VERSION ""

NS_ :

BS_:

BU_: LeanSensor Logger

BO_ 3221225472 VECTOR__INDEPENDENT_SIG_MSG: 0 Vector__XXX
 SG_ lean_1_7 : 0|18@1+ (0.01,0) [0|1310.71] "m" Vector__XXX
 SG_ lean_3_7 : 0|18@1+ (0.01,0) [0|1310.71] "m" Vector__XXX
 SG_ lean_3_8 : 0|18@1+ (0.01,0) [0|1310.71] "m" Vector__XXX
 SG_ lean_4_1 : 0|18@1+ (0.01,0) [0|1310.71] "m" Vector__XXX
 SG_ lean_4_2 : 0|18@1+ (0.01,0) [0|1310.71] "m" Vector__XXX
 SG_ lean_4_3 : 0|18@1+ (0.01,0) [0|1310.71] "m" Vector__XXX
 SG_ lean_4_4 : 0|18@1+ (0.01,0) [0|1310.71] "m" Vector__XXX
 SG_ lean_4_5 : 0|18@1+ (0.01,0) [0|1310.71] "m" Vector__XXX
 SG_ lean_4_6 : 0|18@1+ (0.01,0) [0|1310.71] "m" Vector__XXX
 SG_ lean_4_7 : 0|18@1+ (0.01,0) [0|1310.71] "m" Vector__XXX
 SG_ lean_4_8 : 0|18@1+ (0.01,0) [0|1310.71] "m" Vector__XXX
 SG_ lean_5_1 : 0|18@1+ (0.01,0) [0|1310.71] "m" Vector__XXX
 SG_ lean_5_2 : 0|18@1+ (0.01,0) [0|1310.71] "m" Vector__XXX
 SG_ lean_5_3 : 0|18@1+ (0.01,0) [0|1310.71] "m" Vector__XXX
 SG_ lean_5_4 : 0|18@1+ (0.01,0) [0|1310.71] "m" Vector__XXX
 SG_ lean_5_5 : 0|18@1+ (0.01,0) [0|1310.71] "m" Vector__XXX
 SG_ lean_5_6 : 0|18@1+ (0.01,0) [0|1310.71] "m" Vector__XXX
 SG_ lean_5_7 : 0|18@1+ (0.01,0) [0|1310.71] "m" Vector__XXX
 SG_ lean_5_8 : 0|18@1+ (0.01,0) [0|1310.71] "m" Vector__XXX
 SG_ lean_6_1 : 0|18@1+ (0.01,0) [0|1310.71] "m" Vector__XXX
 SG_ lean_6_2 : 0|18@1+ (0.01,0) [0|1310.71] "m" Vector__XXX
 SG_ lean_6_3 : 0|18@1+ (0.01,0) [0|1310.71] "m" Vector__XXX
 SG_ lean_6_4 : 0|18@1+ (0.01,0) [0|1310.71] "m" Vector__XXX
 SG_ lean_6_5 : 0|18@1+ (0.01,0) [0|1310.71] "m" Vector__XXX
 SG_ lean_6_6 : 0|18@1+ (0.01,0) [0|1310.71] "m" Vector__XXX
 SG_ lean_6_7 : 0|18@1+ (0.01,0) [0|1310.71] "m" Vector__XXX
 SG_ lean_6_8 : 0|18@1+ (0.01,0) [0|1310.71] "m" Vector__XXX
 SG_ lean_7_1 : 0|18@1+ (0.01,0) [0|1310.71] "m" Vector__XXX
 SG_ lean_7_2 : 0|18@1+ (0.01,0) [0|1310.71] "m" Vector__XXX
 SG_ lean_7_3 : 0|18@1+ (0.01,0) [0|1310.71] "m" Vector__XXX
 SG_ lean_7_4 : 0|18@1+ (0.01,0) [0|1310.71] "m" Vector__XXX
 SG_ lean_7_5 : 0|18@1+ (0.01,0) [0|1310.71] "m" Vector__XXX
 SG_ lean_7_6 : 0|18@1+ (0.01,0) [0|1310.71] "m" Vector__XXX
 SG_ lean_7_7 : 0|18@1+ (0.01,0) [0|1310.71] "m" Vector__XXX
 SG_ lean_7_8 : 0|18@1+ (0.01,0) [0|1310.71] "m" Vector__XXX
 SG_ lean_8_1 : 0|18@1+ (0.01,0) [0|1310.71] "m" Vector__XXX
 SG_ lean_8_2 : 0|18@1+ (0.01,0) [0|1310.71] "m" Vector__XXX
 SG_ lean_8_3 : 0|18@1+ (0.01,0) [0|1310.71] "m" Vector__XXX
 SG_ lean_8_4 : 0|18@1+ (0.01,0) [0|1310.71] "m" Vector__XXX
 SG_ lean_8_5 : 0|18@1+ (0.01,0) [0|1310.71] "m" Vector__XXX
 SG_ lean_8_6 : 0|18@1+ (0.01,0) [0|1310.71] "m" Vector__XXX
 SG_ lean_8_7 : 0|18@1+ (0.01,0) [0|1310.71] "m" Vector__XXX
 SG_ lean_8_8 : 0|18@1+ (0.01,0) [0|1310.71] "m" Vector__XXX

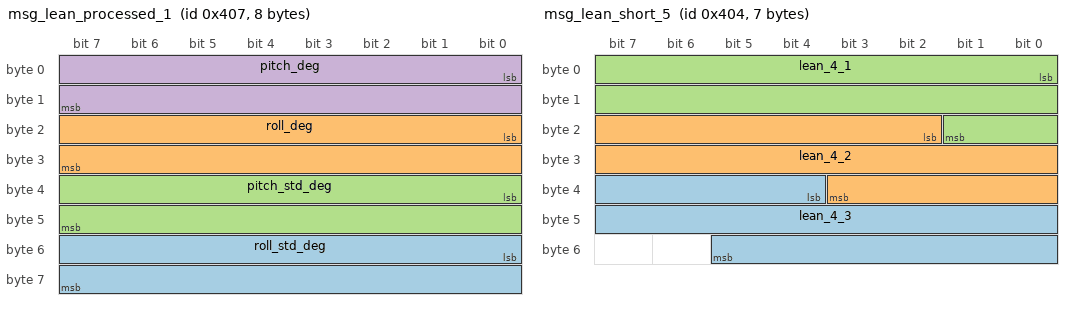
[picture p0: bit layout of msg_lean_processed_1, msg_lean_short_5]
BO_ 1031 msg_lean_processed_1: 8 LeanSensor
 SG_ roll_std_deg : 48|16@1+ (0.001,0) [0|65.535] "m" Vector__XXX
 SG_ roll_deg : 16|16@1- (0.003,0) [-98.304|98.301] "m" Vector__XXX
 SG_ pitch_std_deg : 32|16@1+ (0.001,0) [0|65.535] "m" Vector__XXX
 SG_ pitch_deg : 0|16@1- (0.003,0) [-98.304|98.301] "m" Vector__XXX

BO_ 1029 msg_lean_short_6: 7 LeanSensor
 SG_ lean_4_4 : 0|18@1+ (0.01,0) [0|2621.43] "m" Vector__XXX

BO_ 1028 msg_lean_short_5: 7 LeanSensor
 SG_ lean_4_3 : 36|18@1+ (0.01,0) [0|1310.71] "m" Vector__XXX
 SG_ lean_4_2 : 18|18@1+ (0.01,0) [0|1310.71] "m" Vector__XXX
 SG_ lean_4_1 : 0|18@1+ (0.01,0) [0|2621.43] "m" Vector__XXX

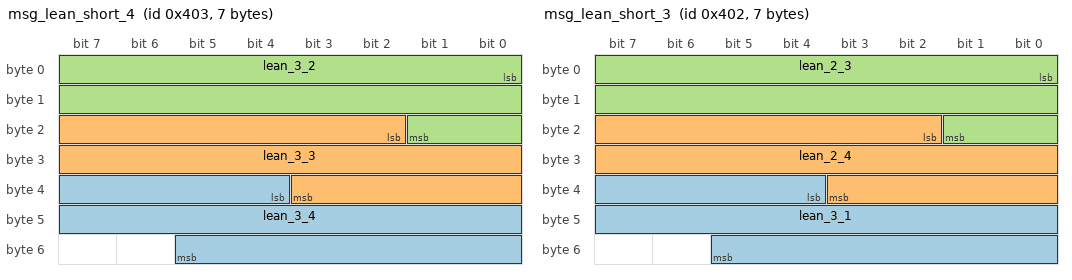
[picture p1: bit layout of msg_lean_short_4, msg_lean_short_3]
BO_ 1027 msg_lean_short_4: 7 LeanSensor
 SG_ lean_3_4 : 36|18@1+ (0.01,0) [0|1310.71] "m" Vector__XXX
 SG_ lean_3_3 : 18|18@1+ (0.01,0) [0|1310.71] "m" Vector__XXX
 SG_ lean_3_2 : 0|18@1+ (0.01,0) [0|2621.43] "m" Vector__XXX

BO_ 1026 msg_lean_short_3: 7 LeanSensor
 SG_ lean_3_1 : 36|18@1+ (0.01,0) [0|1310.71] "m" Vector__XXX
 SG_ lean_2_4 : 18|18@1+ (0.01,0) [0|1310.71] "m" Vector__XXX
 SG_ lean_2_3 : 0|18@1+ (0.01,0) [0|2621.43] "m" Vector__XXX

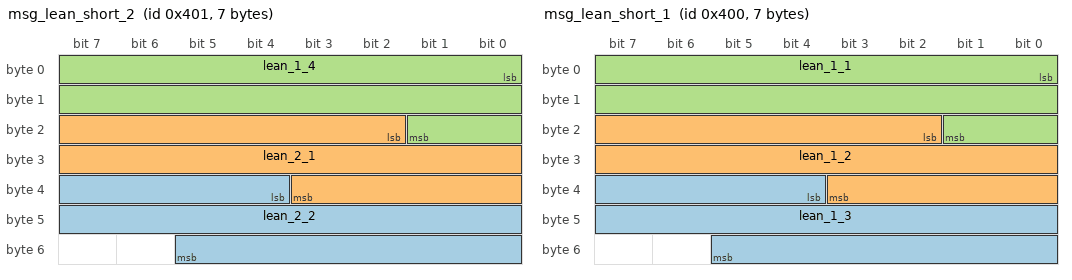
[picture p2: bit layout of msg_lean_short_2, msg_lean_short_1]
BO_ 1025 msg_lean_short_2: 7 LeanSensor
 SG_ lean_2_2 : 36|18@1+ (0.01,0) [0|1310.71] "m" Vector__XXX
 SG_ lean_2_1 : 18|18@1+ (0.01,0) [0|1310.71] "m" Vector__XXX
 SG_ lean_1_4 : 0|18@1+ (0.01,0) [0|2621.43] "m" Vector__XXX

BO_ 1024 msg_lean_short_1: 7 LeanSensor
 SG_ lean_1_3 : 36|18@1+ (0.01,0) [0|1310.71] "m" Vector__XXX
 SG_ lean_1_2 : 18|18@1+ (0.01,0) [0|1310.71] "m" Vector__XXX
 SG_ lean_1_1 : 0|18@1+ (0.01,0) [0|2621.43] "m" Vector__XXX

BO_ 789 msg_lean_long_22: 3 LeanSensor
 SG_ lean_8_8 : 0|18@1+ (0.01,0) [0|1310.71] "m" Vector__XXX

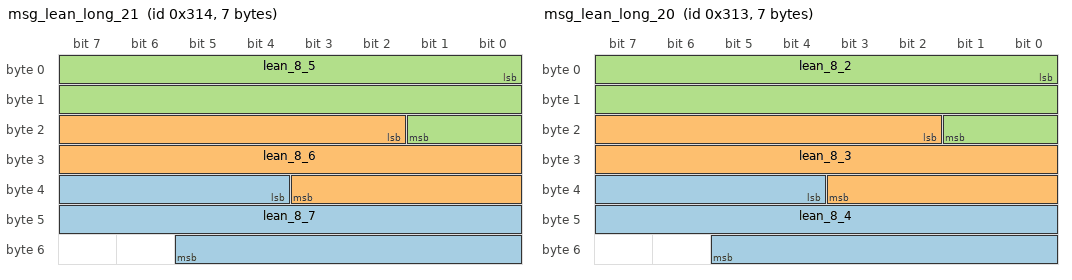
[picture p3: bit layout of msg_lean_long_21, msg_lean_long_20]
BO_ 788 msg_lean_long_21: 7 LeanSensor
 SG_ lean_8_7 : 36|18@1+ (0.01,0) [0|1310.71] "m" Vector__XXX
 SG_ lean_8_6 : 18|18@1+ (0.01,0) [0|1310.71] "m" Vector__XXX
 SG_ lean_8_5 : 0|18@1+ (0.01,0) [0|1310.71] "m" Vector__XXX

BO_ 787 msg_lean_long_20: 7 LeanSensor
 SG_ lean_8_4 : 36|18@1+ (0.01,0) [0|1310.71] "m" Vector__XXX
 SG_ lean_8_3 : 18|18@1+ (0.01,0) [0|1310.71] "m" Vector__XXX
 SG_ lean_8_2 : 0|18@1+ (0.01,0) [0|1310.71] "m" Vector__XXX

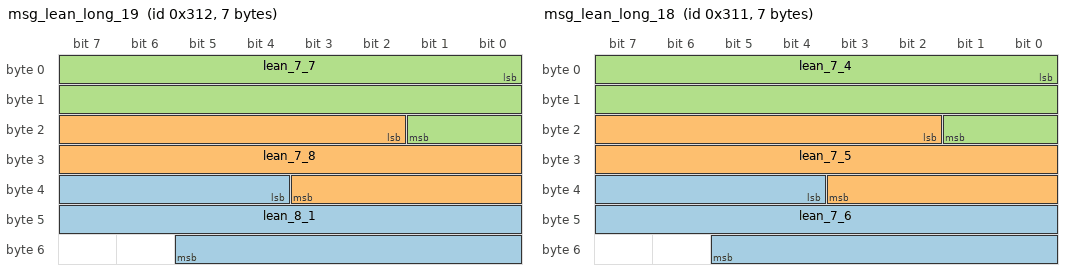
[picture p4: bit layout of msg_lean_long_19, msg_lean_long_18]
BO_ 786 msg_lean_long_19: 7 LeanSensor
 SG_ lean_8_1 : 36|18@1+ (0.01,0) [0|1310.71] "m" Vector__XXX
 SG_ lean_7_8 : 18|18@1+ (0.01,0) [0|1310.71] "m" Vector__XXX
 SG_ lean_7_7 : 0|18@1+ (0.01,0) [0|1310.71] "m" Vector__XXX

BO_ 785 msg_lean_long_18: 7 LeanSensor
 SG_ lean_7_6 : 36|18@1+ (0.01,0) [0|1310.71] "m" Vector__XXX
 SG_ lean_7_5 : 18|18@1+ (0.01,0) [0|1310.71] "m" Vector__XXX
 SG_ lean_7_4 : 0|18@1+ (0.01,0) [0|1310.71] "m" Vector__XXX

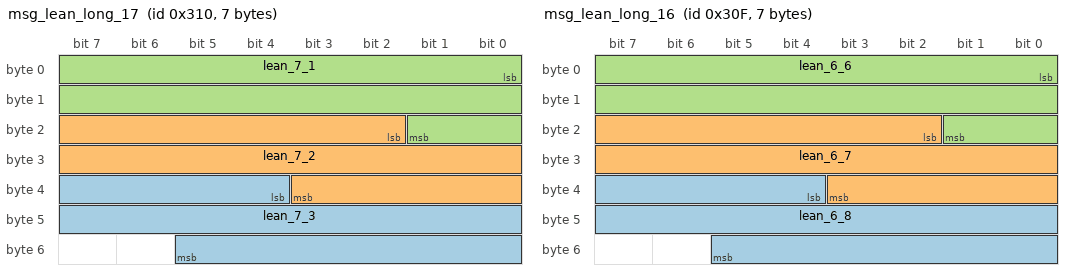
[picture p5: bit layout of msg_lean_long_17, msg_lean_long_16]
BO_ 784 msg_lean_long_17: 7 LeanSensor
 SG_ lean_7_3 : 36|18@1+ (0.01,0) [0|1310.71] "m" Vector__XXX
 SG_ lean_7_2 : 18|18@1+ (0.01,0) [0|1310.71] "m" Vector__XXX
 SG_ lean_7_1 : 0|18@1+ (0.01,0) [0|1310.71] "m" Vector__XXX

BO_ 783 msg_lean_long_16: 7 LeanSensor
 SG_ lean_6_8 : 36|18@1+ (0.01,0) [0|1310.71] "m" Vector__XXX
 SG_ lean_6_7 : 18|18@1+ (0.01,0) [0|1310.71] "m" Vector__XXX
 SG_ lean_6_6 : 0|18@1+ (0.01,0) [0|1310.71] "m" Vector__XXX

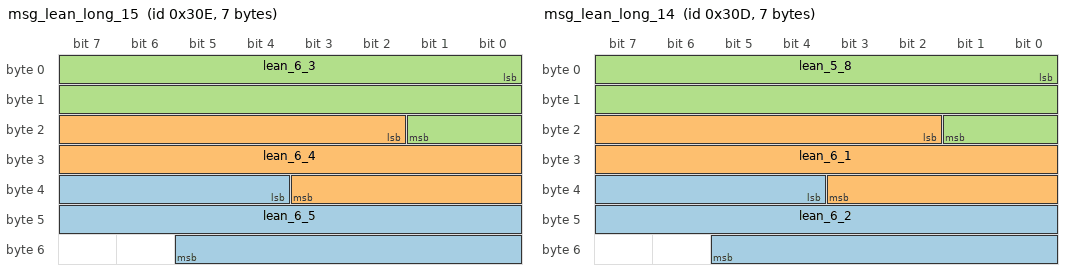
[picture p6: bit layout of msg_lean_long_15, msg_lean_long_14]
BO_ 782 msg_lean_long_15: 7 LeanSensor
 SG_ lean_6_5 : 36|18@1+ (0.01,0) [0|1310.71] "m" Vector__XXX
 SG_ lean_6_4 : 18|18@1+ (0.01,0) [0|1310.71] "m" Vector__XXX
 SG_ lean_6_3 : 0|18@1+ (0.01,0) [0|1310.71] "m" Vector__XXX

BO_ 781 msg_lean_long_14: 7 LeanSensor
 SG_ lean_6_2 : 36|18@1+ (0.01,0) [0|1310.71] "m" Vector__XXX
 SG_ lean_6_1 : 18|18@1+ (0.01,0) [0|1310.71] "m" Vector__XXX
 SG_ lean_5_8 : 0|18@1+ (0.01,0) [0|1310.71] "m" Vector__XXX

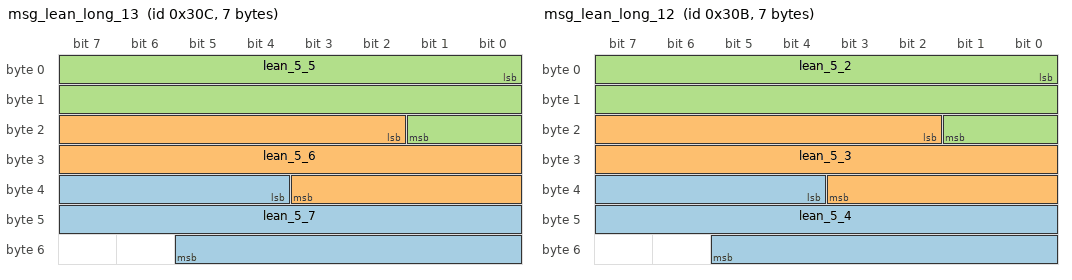
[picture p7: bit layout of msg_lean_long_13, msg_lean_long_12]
BO_ 780 msg_lean_long_13: 7 LeanSensor
 SG_ lean_5_7 : 36|18@1+ (0.01,0) [0|1310.71] "m" Vector__XXX
 SG_ lean_5_6 : 18|18@1+ (0.01,0) [0|1310.71] "m" Vector__XXX
 SG_ lean_5_5 : 0|18@1+ (0.01,0) [0|1310.71] "m" Vector__XXX

BO_ 779 msg_lean_long_12: 7 LeanSensor
 SG_ lean_5_4 : 36|18@1+ (0.01,0) [0|1310.71] "m" Vector__XXX
 SG_ lean_5_3 : 18|18@1+ (0.01,0) [0|1310.71] "m" Vector__XXX
 SG_ lean_5_2 : 0|18@1+ (0.01,0) [0|2621.43] "m" Vector__XXX

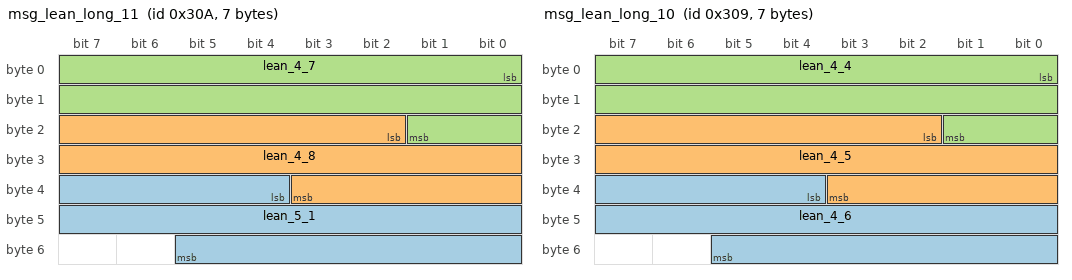
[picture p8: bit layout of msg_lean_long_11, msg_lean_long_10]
BO_ 778 msg_lean_long_11: 7 LeanSensor
 SG_ lean_5_1 : 36|18@1+ (0.01,0) [0|1310.71] "m" Vector__XXX
 SG_ lean_4_8 : 18|18@1+ (0.01,0) [0|1310.71] "m" Vector__XXX
 SG_ lean_4_7 : 0|18@1+ (0.01,0) [0|1310.71] "m" Vector__XXX

BO_ 777 msg_lean_long_10: 7 LeanSensor
 SG_ lean_4_6 : 36|18@1+ (0.01,0) [0|1310.71] "m" Vector__XXX
 SG_ lean_4_5 : 18|18@1+ (0.01,0) [0|1310.71] "m" Vector__XXX
 SG_ lean_4_4 : 0|18@1+ (0.01,0) [0|1310.71] "m" Vector__XXX

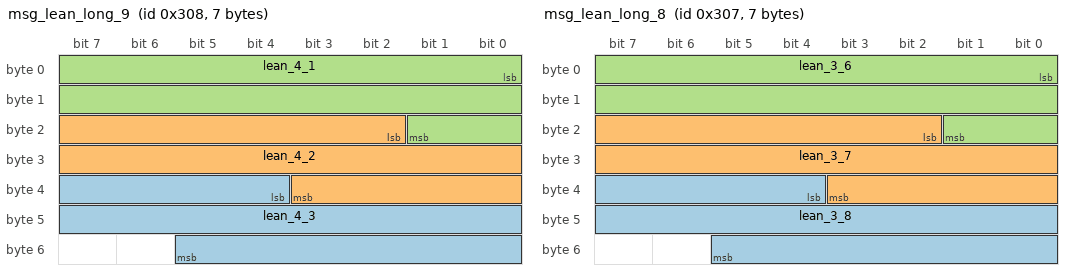
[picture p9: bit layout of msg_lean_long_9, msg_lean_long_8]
BO_ 776 msg_lean_long_9: 7 LeanSensor
 SG_ lean_4_3 : 36|18@1+ (0.01,0) [0|1310.71] "m" Vector__XXX
 SG_ lean_4_2 : 18|18@1+ (0.01,0) [0|1310.71] "m" Vector__XXX
 SG_ lean_4_1 : 0|18@1+ (0.01,0) [0|1310.71] "m" Vector__XXX

BO_ 775 msg_lean_long_8: 7 LeanSensor
 SG_ lean_3_8 : 36|18@1+ (0.01,0) [0|1310.71] "m" Vector__XXX
 SG_ lean_3_7 : 18|18@1+ (0.01,0) [0|1310.71] "m" Vector__XXX
 SG_ lean_3_6 : 0|18@1+ (0.01,0) [0|1310.71] "m" Vector__XXX

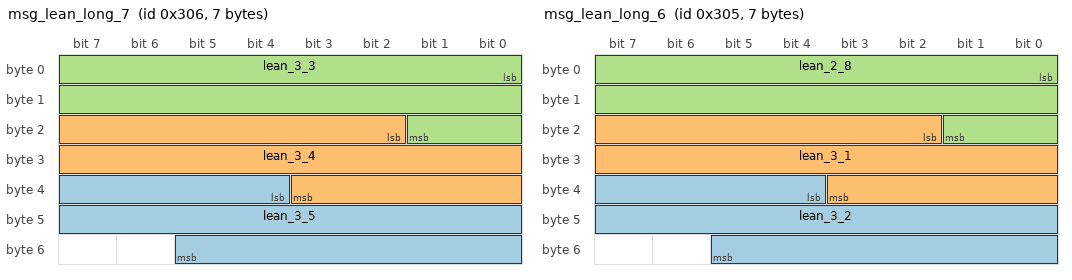
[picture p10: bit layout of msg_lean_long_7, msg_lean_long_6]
BO_ 774 msg_lean_long_7: 7 LeanSensor
 SG_ lean_3_5 : 36|18@1+ (0.01,0) [0|1310.71] "m" Vector__XXX
 SG_ lean_3_4 : 18|18@1+ (0.01,0) [0|1310.71] "m" Vector__XXX
 SG_ lean_3_3 : 0|18@1+ (0.01,0) [0|1310.71] "m" Vector__XXX

BO_ 773 msg_lean_long_6: 7 LeanSensor
 SG_ lean_3_2 : 36|18@1+ (0.01,0) [0|1310.71] "m" Vector__XXX
 SG_ lean_3_1 : 18|18@1+ (0.01,0) [0|1310.71] "m" Vector__XXX
 SG_ lean_2_8 : 0|18@1+ (0.01,0) [0|1310.71] "m" Vector__XXX

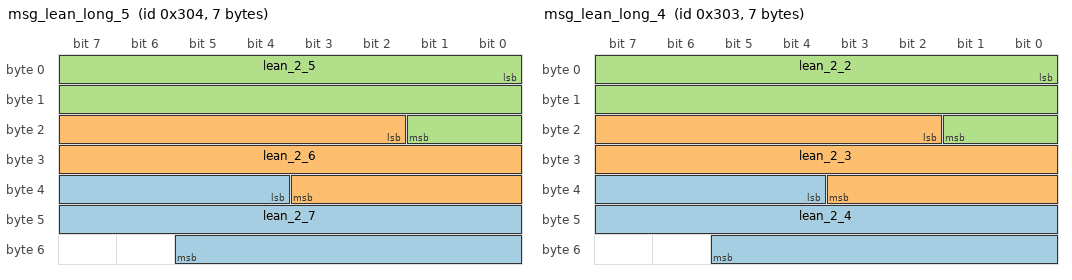
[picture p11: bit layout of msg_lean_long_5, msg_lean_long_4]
BO_ 772 msg_lean_long_5: 7 LeanSensor
 SG_ lean_2_7 : 36|18@1+ (0.01,0) [0|1310.71] "m" Vector__XXX
 SG_ lean_2_6 : 18|18@1+ (0.01,0) [0|1310.71] "m" Vector__XXX
 SG_ lean_2_5 : 0|18@1+ (0.01,0) [0|1310.71] "m" Vector__XXX

BO_ 771 msg_lean_long_4: 7 LeanSensor
 SG_ lean_2_4 : 36|18@1+ (0.01,0) [0|1310.71] "m" Vector__XXX
 SG_ lean_2_3 : 18|18@1+ (0.01,0) [0|1310.71] "m" Vector__XXX
 SG_ lean_2_2 : 0|18@1+ (0.01,0) [0|1310.71] "m" Vector__XXX

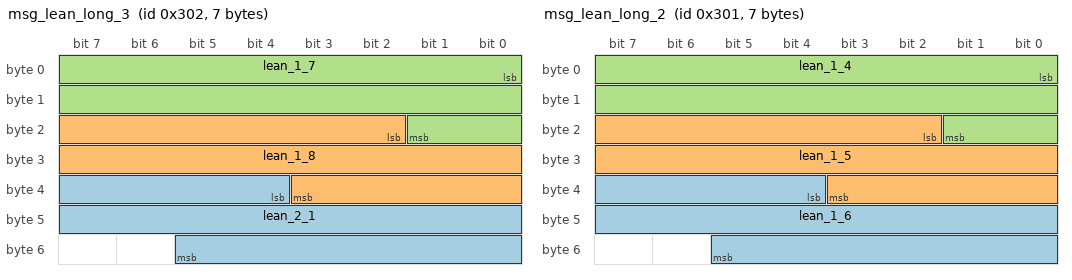
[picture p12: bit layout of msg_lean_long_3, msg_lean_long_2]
BO_ 770 msg_lean_long_3: 7 LeanSensor
 SG_ lean_2_1 : 36|18@1+ (0.01,0) [0|1310.71] "m" Vector__XXX
 SG_ lean_1_8 : 18|18@1+ (0.01,0) [0|1310.71] "m" Vector__XXX
 SG_ lean_1_7 : 0|18@1+ (0.01,0) [0|1310.71] "m" Vector__XXX

BO_ 769 msg_lean_long_2: 7 LeanSensor
 SG_ lean_1_6 : 36|18@1+ (0.01,0) [0|1310.71] "m" Vector__XXX
 SG_ lean_1_5 : 18|18@1+ (0.01,0) [0|1310.71] "m" Vector__XXX
 SG_ lean_1_4 : 0|18@1+ (0.01,0) [0|1310.71] "m" Vector__XXX

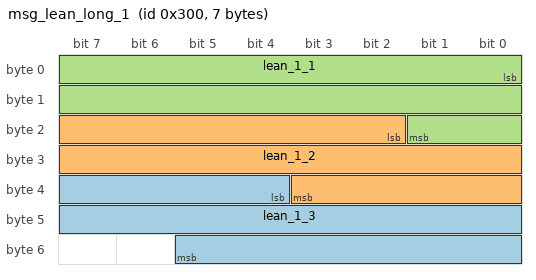
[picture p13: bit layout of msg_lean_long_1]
BO_ 768 msg_lean_long_1: 7 LeanSensor
 SG_ lean_1_3 : 36|18@1+ (0.01,0) [0|1310.71] "m" Vector__XXX
 SG_ lean_1_2 : 18|18@1+ (0.01,0) [0|1310.71] "m" Vector__XXX
 SG_ lean_1_1 : 0|18@1+ (0.01,0) [0|2621.43] "m" Vector__XXX

CM_ BO_ 3221225472 "This is a message for not used signals, created by Vector CANdb++ DBC OLE DB Provider.";
BA_DEF_ BO_  "J1939PgAppearanceOnBus" ENUM  "Default","CAN_Extended","CANFD_Extended";
BA_DEF_ BO_  "J1939CPgSendTimeout" INT -1 3600000;
BA_DEF_ BO_  "J1939CPgTOS" INT 0 7;
BA_DEF_ BU_  "J1939MultiPgSendTimeout" INT 0 3600000;
BA_DEF_ BU_  "J1939MultiPgSizeThreshold" INT 0 64;
BA_DEF_ BU_  "J1939MultiPgBroadcastType" ENUM  "FBFF","FEFF";
BA_DEF_ SG_  "SigType" ENUM  "Default","Range","RangeSigned","ASCII","Discrete","Control","ReferencePGN","DTC","StringDelimiter","StringLength","StringLengthControl","MessageCounter","MessageChecksum";
BA_DEF_ SG_  "GenSigILSupport" ENUM  "No","Yes";
BA_DEF_ SG_  "GenSigSendType" ENUM  "Cyclic","OnWrite","OnWriteWithRepetition","OnChange","OnChangeWithRepetition","IfActive","IfActiveWithRepetition","NoSigSendType";
BA_DEF_ SG_  "GenSigStartValue" INT 0 2147483647;
BA_DEF_ BO_  "GenMsgILSupport" ENUM  "No","Yes";
BA_DEF_ BU_  "NmStationAddress" INT 0 255;
BA_DEF_ BO_  "GenMsgSendType" ENUM  "cyclic","NotUsed","NotUsed","NotUsed","NotUsed","NotUsed","NotUsed","IfActive","noMsgSendType";
BA_DEF_ BO_  "GenMsgRequestable" INT 0 1;
BA_DEF_  "DBName" STRING ;
BA_DEF_  "BusType" STRING ;
BA_DEF_  "ProtocolType" STRING ;
BA_DEF_ BO_  "VFrameFormat" ENUM  "StandardCAN","ExtendedCAN","reserved","J1939PG","reserved","reserved","reserved","reserved","reserved","reserved","reserved","reserved","reserved","reserved","StandardCAN_FD","ExtendedCAN_FD";
BA_DEF_DEF_  "J1939PgAppearanceOnBus" "Default";
BA_DEF_DEF_  "J1939CPgSendTimeout" -1;
BA_DEF_DEF_  "J1939CPgTOS" 2;
BA_DEF_DEF_  "J1939MultiPgSendTimeout" 2;
BA_DEF_DEF_  "J1939MultiPgSizeThreshold" 56;
BA_DEF_DEF_  "J1939MultiPgBroadcastType" "FBFF";
BA_DEF_DEF_  "SigType" "Default";
BA_DEF_DEF_  "GenSigILSupport" "Yes";
BA_DEF_DEF_  "GenSigSendType" "NoSigSendType";
BA_DEF_DEF_  "GenSigStartValue" 0;
BA_DEF_DEF_  "GenMsgILSupport" "Yes";
BA_DEF_DEF_  "NmStationAddress" 254;
BA_DEF_DEF_  "GenMsgSendType" "noMsgSendType";
BA_DEF_DEF_  "GenMsgRequestable" 1;
BA_DEF_DEF_  "DBName" "";
BA_DEF_DEF_  "BusType" "CAN";
BA_DEF_DEF_  "ProtocolType" "J1939";
BA_DEF_DEF_  "VFrameFormat" "J1939PG";
BA_ "DBName" "messages";
BA_ "NmStationAddress" BU_ LeanSensor 239;
BA_ "VFrameFormat" BO_ 1031 0;
BA_ "VFrameFormat" BO_ 1029 0;
BA_ "VFrameFormat" BO_ 1028 0;
BA_ "VFrameFormat" BO_ 1027 0;
BA_ "VFrameFormat" BO_ 1026 0;
BA_ "VFrameFormat" BO_ 1025 0;
BA_ "VFrameFormat" BO_ 1024 0;
BA_ "VFrameFormat" BO_ 789 0;
BA_ "VFrameFormat" BO_ 788 0;
BA_ "VFrameFormat" BO_ 787 0;
BA_ "VFrameFormat" BO_ 786 0;
BA_ "VFrameFormat" BO_ 785 0;
BA_ "VFrameFormat" BO_ 784 0;
BA_ "VFrameFormat" BO_ 783 0;
BA_ "VFrameFormat" BO_ 782 0;
BA_ "VFrameFormat" BO_ 781 0;
BA_ "VFrameFormat" BO_ 780 0;
BA_ "VFrameFormat" BO_ 779 0;
BA_ "VFrameFormat" BO_ 778 0;
BA_ "VFrameFormat" BO_ 777 0;
BA_ "VFrameFormat" BO_ 776 0;
BA_ "VFrameFormat" BO_ 775 0;
BA_ "VFrameFormat" BO_ 774 0;
BA_ "VFrameFormat" BO_ 773 0;
BA_ "VFrameFormat" BO_ 772 0;
BA_ "VFrameFormat" BO_ 771 0;
BA_ "VFrameFormat" BO_ 770 0;
BA_ "VFrameFormat" BO_ 769 0;
BA_ "VFrameFormat" BO_ 768 0;
